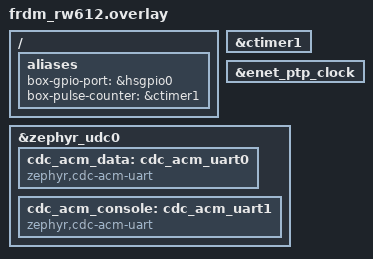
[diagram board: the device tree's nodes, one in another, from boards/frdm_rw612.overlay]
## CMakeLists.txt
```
# extio-rw612 -- Zephyr application (freestanding; builds against $ZEPHYR_BASE).
#
#   west build -b native_sim  <this-dir>     # host smoke test, no board
#   west build -b frdm_rw612  <this-dir>     # the target
#
cmake_minimum_required(VERSION 3.20.0)

find_package(Zephyr REQUIRED HINTS $ENV{ZEPHYR_BASE})
project(extio_rw612 LANGUAGES C)

# Common to every board: core + GPIO + USB transport + the uplink arbiter.
target_sources(app PRIVATE
	src/main.c
	src/platform/box_gpio.c        # block #3: GPIO + hardware-counter pulse
	src/platform/box_usbd.c        # block #4: USB device (device_next) context
	src/platform/box_net_usb.c     # block #4: CDC-ACM frame transport
	src/platform/box_uplink.c      # block #6: uplink arbiter
)

# Ethernet + PTP: frdm_rw612 and teensy41 (teensy40 has no PHY).
if(CONFIG_NETWORKING)
	target_sources(app PRIVATE
		src/platform/box_net_eth.c     # block #5: Ethernet transport (sockets)
		src/platform/box_ptp.c         # block #5: ENET IEEE-1588 hardware clock
	)
endif()

# BLE ingress: frdm_rw612 only (no radio on Teensy).
if(CONFIG_BT)
	target_sources(app PRIVATE
		src/platform/box_ble.c         # block #6: multi-peripheral BLE central
	)
endif()

# The portable core (forked from wiznet-io, pico_* -> box_*) plus the RW612/Zephyr
# platform layer, added building-block by building-block.
target_include_directories(app PRIVATE src/core src/platform)
```

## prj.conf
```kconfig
# extio-rw612 -- COMMON config for every supported board.
# Board-specific subsystems live in boards/<board>.conf (auto-merged by Zephyr):
#   frdm_rw612 -> Ethernet+PTP + BLE      (the universal hub)
#   teensy41   -> Ethernet+PTP, no radio  (wired test system)
#   teensy40   -> USB only                (USB-HS test system)

CONFIG_PRINTK=y
CONFIG_CBPRINTF_FP_SUPPORT=n

# block #3: box_gpio -- DO/DI via the box-gpio-port alias, box-timed pulse on a
# hardware counter via the box-pulse-counter alias (both set per board).
CONFIG_GPIO=y
CONFIG_COUNTER=y

# block #4: USB-HS CDC transport. device_next stack (High-Speed on both the
# RW612 and the RT1062), CDC-ACM frame pipe + console, irq-driven UART + DTR.
CONFIG_USB_DEVICE_STACK_NEXT=y
CONFIG_USBD_CDC_ACM_CLASS=y
CONFIG_UART_INTERRUPT_DRIVEN=y
CONFIG_UART_LINE_CTRL=y
CONFIG_RING_BUFFER=y
CONFIG_HWINFO=y            # USB serial number derived from the device HWID

# headroom for the net stack where it is enabled; harmless otherwise
CONFIG_MAIN_STACK_SIZE=4096

# CONFIG_ADC=y             # block #7: GAU GPADC vs external MCP3204
# CONFIG_SETTINGS=y        # persistence backend for box_persist
```

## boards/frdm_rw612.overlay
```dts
/*
 * extio-rw612 devicetree overlay for the FRDM-RW612.
 *
 * Enable ctimer1 as the hardware pulse timer for box_gpio's non-blocking,
 * box-timed DO pulses (ctimer0 is already claimed by the board). The Zephyr
 * counter driver (nxp,lpc-ctimer) binds to it, giving us up to 4 match channels
 * of µs-precision, CPU-free pulse timing -- the RW612 analog of the RP2350
 * alarm pool.
 */
/ {
	aliases {
		box-gpio-port     = &hsgpio0;   /* box pin n -> hsgpio0.n (12 = user LED) */
		box-pulse-counter = &ctimer1;   /* hardware box-timed pulse               */
	};
};

&ctimer1 {
	status = "okay";
};

/*
 * Enable the ENET IEEE-1588 hardware clock (block #5). The board enables the MAC
 * and MDIO but leaves this node disabled; turning it on instantiates the PTP
 * clock device (PTP_CLOCK_NXP_ENET), the sub-µs sync enabler.
 */
&enet_ptp_clock {
	status = "okay";
};

/*
 * Two USB CDC-ACM instances on the HS device controller (block #4):
 *   cdc_acm_data    -- the binary 128-byte dserv frame pipe (data + config)
 *   cdc_acm_console -- the human text console / bootstrap CLI
 * This is the "config alongside the data pump" split: both channels are the same
 * USB primitive, differentiated by role. The frame pipe can later move to raw
 * vendor bulk endpoints without touching the box logic (see BENCH_NXP.md D1/D2).
 */
&zephyr_udc0 {
	cdc_acm_data: cdc_acm_uart0 {
		compatible = "zephyr,cdc-acm-uart";
	};
	cdc_acm_console: cdc_acm_uart1 {
		compatible = "zephyr,cdc-acm-uart";
	};
};
```

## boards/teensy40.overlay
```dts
/*
 * extio-rw612 on a PJRC Teensy 4.0 (i.MX RT1062) -- the USB-only test system.
 *
 * Same silicon as the 4.1 but no Ethernet PHY, so this build is the USB-HS box:
 * a direct A/B against the Pico 2's USB-FS transport (12 Mbps vs 480 Mbps).
 * No radio, so no BLE (see boards/teensy40.conf).
 */
/ {
	aliases {
		box-gpio-port     = &gpio2;   /* box pin n -> gpio2.n (3 = board LED) */
		box-pulse-counter = &gpt2;    /* hardware box-timed pulse             */
	};
};

&gpt2 {
	status = "okay";
};

&zephyr_udc0 {
	cdc_acm_data: cdc_acm_uart0 {
		compatible = "zephyr,cdc-acm-uart";
	};
	cdc_acm_console: cdc_acm_uart1 {
		compatible = "zephyr,cdc-acm-uart";
	};
};
```

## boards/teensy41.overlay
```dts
/*
 * extio-rw612 on a PJRC Teensy 4.1 (i.MX RT1062) -- the wired test system.
 *
 * The RT1062 drives the same NXP peripherals through the same Zephyr drivers as
 * the RW612: `nxp,enet` + `nxp,enet-ptp-clock` for Ethernet/1588, and a USB-HS
 * device controller. Teensy 4.1's board DTS already enables ENET with a
 * ti,dp83825 PHY (RMII) -- add a magjack and it's a wired extio box.
 *
 * NOTE: no radio on Teensy, so block #6's BLE ingress is excluded (see
 * boards/teensy41.conf -- no CONFIG_BT). Everything else builds.
 */
/ {
	aliases {
		box-gpio-port     = &gpio2;   /* box pin n -> gpio2.n (3 = board LED) */
		box-pulse-counter = &gpt2;    /* hardware box-timed pulse             */
	};
};

/* GPT2 as the Zephyr counter behind the box-timed DO pulse (the RT1062's
 * equivalent of the RW612's CTIMER). */
&gpt2 {
	status = "okay";
};

/* The ENET IEEE-1588 clock is `disabled` in the RT1060 SoC dtsi exactly as it is
 * on the RW612 -- enable it so PTP_CLOCK_NXP_ENET instantiates the clock. */
&enet_ptp_clock {
	status = "okay";
};

/* Same two CDC-ACM instances as the RW612 build: the binary frame pipe
 * (data + config) and the human text console. */
&zephyr_udc0 {
	cdc_acm_data: cdc_acm_uart0 {
		compatible = "zephyr,cdc-acm-uart";
	};
	cdc_acm_console: cdc_acm_uart1 {
		compatible = "zephyr,cdc-acm-uart";
	};
};
```

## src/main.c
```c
/*
 * extio-rw612 -- Zephyr application entry.
 *
 * Building block #2: prove the portable core (forked verbatim from wiznet-io,
 * pico_* renamed to box_*) compiles and RUNS under the Zephyr toolchain, first
 * on native_sim, then on the FRDM-RW612 board. This is the on-target twin of
 * tools/box_sim.c --selftest: build datapoint frames, dispatch them into a
 * box_config_t, exercise a gpio command, and round-trip persist -- all with
 * zero platform dependencies beyond printk.
 *
 * The transport/GPIO/flash platform layer (src/platform/) is deliberately NOT
 * wired yet; that is building block #3+ (USB-HS, Ethernet+PTP, BLE, GAU ADC).
 */
#include <zephyr/kernel.h>
#include <zephyr/version.h>
#include <stdio.h>

#include "dserv_config.h"
#include "box_persist.h"
#include "box_gpio.h"
#include "box_net_usb.h"
#include "box_uplink.h"
#if defined(CONFIG_NETWORKING)
#include "box_net_eth.h"
#include "box_ptp.h"
#endif
#if defined(CONFIG_BT)
#include "box_ble.h"
#endif

static box_config_t   cfg;
static dserv_framer_t rx_framer;

/* Demo pins, per board. box pin n -> <box-gpio-port>.n (see box_gpio.h), so
 * these land on real hardware on each target. */
#if defined(CONFIG_BOARD_FRDM_RW612)
#define LED_PIN  12   /* hsgpio0.12 = user LED (active low physically) */
#define BTN_PIN  11   /* hsgpio0.11 = User SW2 (active low, pull-up)    */
#else                 /* Teensy 4.x: board LED is gpio2.3 */
#define LED_PIN  3    /* gpio2.3 = on-board LED                         */
#define BTN_PIN  4    /* gpio2.4 = a free pin for a test button         */
#endif

/* One inbound 128-byte frame (config/cmd/ess-in_obs) from the host module:
 * dispatch it into the config, and run any GPIO command it produced. */
static void on_usb_frame(const uint8_t *frame, void *ud)
{
	ARG_UNUSED(ud);
	dserv_msg_t m;
	if (dserv_msg_parse(frame, &m) != 0) {
		return;
	}
	gpio_cmd_t cmd;
	cfg_result_t r = dserv_dispatch(&cfg, &m, &cmd);
	if (r == CFG_GPIO && cmd.op != GPIO_OP_NONE) {
		box_gpio_exec(&cfg, &cmd);            /* immediate DO set/pulse */
	} else if (r == CFG_PIN_MODE) {
		box_gpio_apply_config(&cfg);          /* re-apply on a pin mode change */
	}
}

static cfg_result_t feed(const uint8_t *frame, gpio_cmd_t *cmd)
{
	dserv_msg_t m;
	if (dserv_msg_parse(frame, &m) != 0) {
		return CFG_NONE;
	}
	return dserv_dispatch(&cfg, &m, cmd);
}

int main(void)
{
	uint8_t f[DSERV_MSG_LEN];
	gpio_cmd_t cmd;
	cfg_result_t r;

	printk("\n=== extio-rw612 core smoke test (Zephyr %s) ===\n", KERNEL_VERSION_STRING);

	/* config datapoint: set pin 5 to output */
	dserv_msg_int(f, "extio/pico/config/pin/5/mode", 0, 1);
	r = feed(f, &cmd);
	printk("apply config/pin/5/mode=out    -> %-9s pin_mode[5]=%u\n",
	       dserv_cfg_result_str(r), cfg.pin_mode[5]);

	/* config datapoint: string-typed dserv IP */
	dserv_msg_string(f, "extio/pico/config/dserv/ip", 0, "192.168.11.1");
	r = feed(f, &cmd);
	printk("apply config/dserv/ip          -> %-9s %u.%u.%u.%u\n",
	       dserv_cfg_result_str(r), cfg.dserv_ip[0], cfg.dserv_ip[1],
	       cfg.dserv_ip[2], cfg.dserv_ip[3]);

	/* transient command: box-timed pulse on pin 6 -> a gpio_cmd for the platform */
	dserv_msg_int(f, "extio/pico/cmd/do/6/pulse_us", 0, 500);
	r = feed(f, &cmd);
	printk("apply cmd/do/6/pulse_us=500    -> %-9s op=%d pin=%u value=%u\n",
	       dserv_cfg_result_str(r), cmd.op, cmd.pin, cmd.value);

	/* persistence round-trip (the flash write itself is platform; the codec is core) */
	uint8_t blob[BOX_PERSIST_BLOB_MAX];
	uint32_t n = box_persist_serialize(&cfg, blob, sizeof blob);
	box_config_t restored = {0};
	int ok = box_persist_deserialize(blob, n, &restored);
	printk("persist round-trip             -> %-9s %u bytes, applied_count=%u\n",
	       ok == 0 ? "ok" : "FAIL", n, restored.applied_count);

	/* the box's datapoint identity */
	char pfx[64];
	dserv_cfg_prefix(&cfg, pfx, sizeof pfx);
	printk("datapoint prefix               -> %s  (dserv port %u)\n",
	       pfx, dserv_cfg_port(&cfg));

	printk("=== codec smoke test done ===\n\n");

	/* ---- block #3: real GPIO on the FRDM-RW612 ---- */
	printk("=== box_gpio hardware test ===\n");
	if (box_gpio_init() != 0) {
		printk("box_gpio_init FAILED (gpio/counter device not ready)\n");
		return 0;
	}

	/* Configure LED pin as output, button pin as pulled-up input, via the same
	 * config path the host uses -- then hand the config to the platform layer. */
	cfg.pin_mode[LED_PIN] = 1;   /* output   */
	cfg.pin_mode[BTN_PIN] = 3;   /* in_pullup */
	box_gpio_apply_config(&cfg);
	printk("configured hsgpio0.%d=out (LED), hsgpio0.%d=in_pullup (SW2)\n",
	       LED_PIN, BTN_PIN);

	/* Boot heartbeat: three hardware-timed LED pulses (CTIMER drops each edge). */
	gpio_cmd_t pulse = { .op = GPIO_OP_PULSE, .pin = LED_PIN, .value = 120000 };
	for (int i = 0; i < 3; i++) {
		box_gpio_exec(&cfg, &pulse);
		k_msleep(250);
	}
	printk("=== box_gpio ready ===\n\n");

	/* ---- blocks #4-6: transports behind the uplink arbiter ---- */
	printk("=== box_uplink (USB + Ethernet, arbitrated) ===\n");
	box_uplink_init(&cfg);          /* brings up both transports; picks the active one */
	dserv_framer_reset(&rx_framer);

#if defined(CONFIG_NETWORKING)
	/* one-shot status: DHCP lease (if eth came up) + the PTP hardware clock */
	uint8_t ip[4];
	if (box_net_eth_wait_ip(ip, 5000)) {
		printk("eth DHCP IPv4: %u.%u.%u.%u  link=%d\n",
		       ip[0], ip[1], ip[2], ip[3], box_net_eth_link());
	} else {
		printk("eth: no lease (link=%d)\n", box_net_eth_link());
	}
	printk("PTP hw clock: ready=%d  now=%llu ns\n",
	       (int) box_ptp_ready(), (unsigned long long) box_ptp_now_ns());
#else
	printk("no Ethernet on this board -- USB-only uplink\n");
#endif
	printk("active uplink: %s\n", box_uplink_active_name());

#if defined(CONFIG_BT)
	/* ---- block #6 (ingress): multi-peripheral BLE central ---- */
	if (box_ble_init() == 0) {
		printk("BLE central up; scanning for d5e7000x peripherals (max %d)\n\n",
		       CONFIG_BT_MAX_CONN);
	} else {
		printk("BLE init failed (continuing wired-only)\n\n");
	}
#else
	printk("no radio on this board -- BLE ingress disabled\n\n");
#endif

	/* ---- converged box service loop (blocks #2-6 together) ----
	 * arbitrate the uplink; inbound frames -> dispatch -> GPIO; local DI, BLE
	 * ingress, and a 1 Hz watchdog -> whichever uplink is active. */
	uint8_t rx[256];
	int watchdog = 0;
	int64_t next_wd = k_uptime_get() + 1000;
	char name[80];

	while (1) {
		box_uplink_service(&cfg);         /* carrier/strap selection + (re)connect */

		int n = box_uplink_poll(rx, sizeof rx);
		if (n == BOX_NET_RESET) {
			dserv_framer_reset(&rx_framer);
		} else if (n > 0) {
			dserv_framer_feed(&rx_framer, rx, (uint32_t) n, on_usb_frame, NULL);
		}

		box_di_event_t ev;
		while (box_gpio_poll_di(&cfg, &ev)) {
			uint8_t f[DSERV_MSG_LEN];
			char leaf[24];
			snprintf(leaf, sizeof leaf, "di/%u", ev.pin);
			dserv_state_name(&cfg, name, sizeof name, leaf);   /* extio/<name>/state/di/<pin> */
			dserv_msg_int(f, name, ev.t_us, ev.level);
			box_uplink_send(f, DSERV_MSG_LEN);
		}

#if defined(CONFIG_BT)
		/* BLE ingress: each peripheral's frame is already source-stamped
		 * (extio/<client>/...); relay it out the active uplink verbatim. */
		uint8_t bframe[DSERV_MSG_LEN];
		while (box_ble_poll(bframe)) {
			box_uplink_send(bframe, DSERV_MSG_LEN);
		}
#endif

		if (k_uptime_get() >= next_wd) {
			next_wd += 1000;
			uint8_t f[DSERV_MSG_LEN];
			dserv_state_name(&cfg, name, sizeof name, "watchdog");
			dserv_msg_int(f, name, 0, watchdog++);
			box_uplink_send(f, DSERV_MSG_LEN);
		}

		k_msleep(1);
	}
	return 0;
}
```
